# ADuCM410 register map
Vendor: Analog Devices; Series: ADuCM410; File version: 1p0
CPU: CM33 r0p1, little endian, MPU, FPU, 3 interrupt priority bits
Registers are 32-bit, read-write, reset 0x0 unless marked. A register's access mark holds for its fields unless they carry their own. Offsets are from the block's base; [hi:lo] are bit positions; {n}, {i} and the like mark numbered series; 'fields as' and 'values as' point back to an identical list.

## I2C0 — Some Description.
Base 0x40020800
Same registers: I2C1 0x40020C00, I2C2 0x40021000
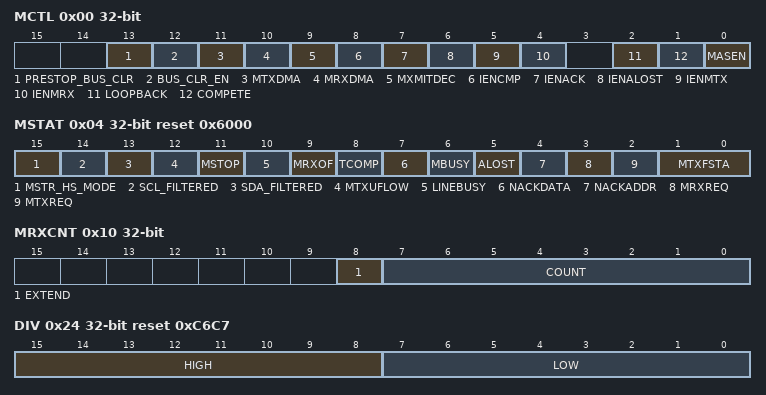
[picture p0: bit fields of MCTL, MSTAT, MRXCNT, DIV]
0x00 MCTL — Master Control
  [13] PRESTOP_BUS_CLR range 0x00000000..0x00000001 — Prestop Bus-Clear
  [12] BUS_CLR_EN range 0x00000000..0x00000001 — Bus-Clear Enable
  [11] MTXDMA wo range 0x00000000..0x00000001 — Enable Master Tx DMA Request
  [10] MRXDMA wo range 0x00000000..0x00000001 — Enable Master Rx DMA Request
  [9] MXMITDEC range 0x00000000..0x00000001 — Decrement Master TX FIFO Status When Transmitted One Byte
  [8] IENCMP range 0x00000000..0x00000001 — Transaction Completed (Or Stop Detected) Interrupt Enable
  [7] IENACK range 0x00000000..0x00000001 — ACK Not Received Interrupt Enable
  [6] IENALOST range 0x00000000..0x00000001 — Arbitration Lost Interrupt Enable
  [5] IENMTX range 0x00000000..0x00000001 — Transmit Request Interrupt Enable.
  [4] IENMRX range 0x00000000..0x00000001 — Receive Request Interrupt Enable
  [2] LOOPBACK range 0x00000000..0x00000001 — Internal Loopback Enable
  [1] COMPETE range 0x00000000..0x00000001 — Start Back-off Disable
  [0] MASEN range 0x00000000..0x00000001 — Master Enable
0x04 MSTAT reset 0x6000 — Master Status
  [15] MSTR_HS_MODE ro — Master High Speed Mode Flag
  [14] SCL_FILTERED ro — State of SCL Line
  [13] SDA_FILTERED ro — State of SDA Line
  [12] MTXUFLOW ro — Master Transmit Underflow
  [11] MSTOP ro — STOP Driven by This I2C Master
  [10] LINEBUSY ro — Line is Busy
  [9] MRXOF ro — Master Receive FIFO Overflow
  [8] TCOMP ro — Transaction Complete or Stop Detected
  [7] NACKDATA ro — ACK Not Received in Response to Data Write
  [6] MBUSY ro — Master Busy
  [5] ALOST ro — Arbitration Lost
  [4] NACKADDR ro — ACK Not Received in Response to an Address
  [3] MRXREQ ro — Master Receive Request
  [2] MTXREQ range 0x00000000..0x00000001 — Master Transmit Interrupt Bit
  [1:0] MTXFSTA ro — Master Transmit FIFO Status
0x08 MRX — Master Receive Data
  [7:0] ICMRX ro — Master Receive Register
0x0C MTX — Master Transmit Data
  [7:0] I2CMRX range 0x00000000..0x000000FF — Master Transmit Register
0x10 MRXCNT — Master Receive Data Count
  [8] EXTEND range 0x00000000..0x00000001 — Extended Read
  [7:0] COUNT range 0x00000000..0x000000FF — Receive Count
0x14 MCRXCNT — Master Current Receive Data Count
  [7:0] COUNT ro — Current Receive Count
0x18 ADDR0 — 1st Master Address Byte
  [7:0] ADR1 range 0x00000000..0x000000FF — Address Byte 1
0x1C ADDR1 — 2nd Master Address Byte
  [7:0] ADR2 range 0x00000000..0x000000FF — Address Byte 2
0x20 BYT — Start Byte
  [7:0] SBYTE range 0x00000000..0x000000FF
0x24 DIV reset 0xC6C7 — Serial Clock Period Divisor
  [15:8] HIGH range 0x00000000..0x000000FF — Serial Clock High Time
  [7:0] LOW range 0x00000000..0x000000FF — Serial Clock Low Time
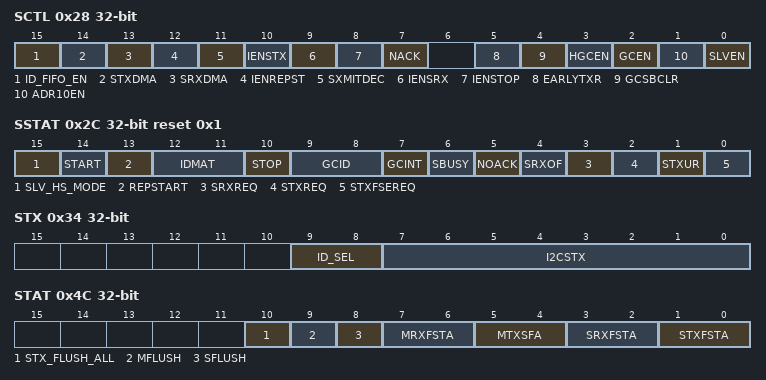
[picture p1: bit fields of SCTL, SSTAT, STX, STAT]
0x28 SCTL — Slave Control
  [15] ID_FIFO_EN range 0x00000000..0x00000001 — ID FIFO Enable
  [14] STXDMA range 0x00000000..0x00000001 — Enable Slave Tx DMA Request
  [13] SRXDMA range 0x00000000..0x00000001 — Enable Slave Rx DMA Request
  [12] IENREPST range 0x00000000..0x00000001 — Repeated Start Interrupt Enable
  [11] SXMITDEC range 0x00000000..0x00000001 — Decrement Slave Tx FIFO Status When Transmitted a Byte
  [10] IENSTX range 0x00000000..0x00000001 — Slave Transmit Request Interrupt Enable
  [9] IENSRX range 0x00000000..0x00000001 — Slave Receive Request Interrupt Enable
  [8] IENSTOP range 0x00000000..0x00000001 — Stop Condition Detected Interrupt Enable
  [7] NACK range 0x00000000..0x00000001 — NACK Next Communication
  [5] EARLYTXR range 0x00000000..0x00000001 — Early Transmit Request Mode
  [4] GCSBCLR wo range 0x00000000..0x00000001 — General Call Status Bit Clear
  [3] HGCEN range 0x00000000..0x00000001 — Hardware General Call Enable
  [2] GCEN range 0x00000000..0x00000001 — General Call Enable
  [1] ADR10EN range 0x00000000..0x00000001 — Enabled 10-bit Addressing
  [0] SLVEN range 0x00000000..0x00000001 — Slave Enable
0x2C SSTAT reset 0x1 — Slave I2C Status/Error/IRQ
  [15] SLV_HS_MODE ro — Slave High Speed Mode Flag
  [14] START ro — Start and Matching Address
  [13] REPSTART ro — Repeated Start and Matching Address
  [12:11] IDMAT ro — Device ID Matched
    {v}=ID{v} (Received Address Matched ID Register {v}) (v=0..3)
  [10] STOP ro — Stop After Start and Matching Address
  [9:8] GCID ro — General ID
    0=NONE (No general call); 1=RESETPROGADDR (General call Reset and Program Address); 2=PROGADDR (General Call Program Address); 3=MATCHID (General Call Matching Alternative ID)
  [7] GCINT ro — General Call Interrupt
  [6] SBUSY ro — Slave Busy
  [5] NOACK ro — Ack Not Generated by the Slave
  [4] SRXOF ro — Slave Receive FIFO Overflow
  [3] SRXREQ ro — Slave Receive Request
  [2] STXREQ ro — Slave Transmit Interrupt Bit
  [1] STXUR ro — Slave Transmit FIFO Underflow
  [0] STXFSEREQ range 0x00000000..0x00000001 — Slave Tx FIFO Status or Early Request
0x30 SRX — Slave Receive
  [7:0] I2CSRX ro — Slave Receive Register
0x34 STX — Slave Transmit
  [9:8] ID_SEL — ID FIFO Selection
    {v}=FIFO{v} (Select Address Matched ID Register {v}) (v=0..3)
  [7:0] I2CSTX range 0x00000000..0x000000FF — Slave Transmit Register
0x38 ALT — Hardware General Call ID
  [7:0] ALT range 0x00000000..0x000000FF — Slave Alt
0x3C ID0 — 1st Slave Address Device ID
  [7:0] ID0 range 0x00000000..0x000000FF — Slave Device ID 0
0x40 ID1 — 2nd Slave Address Device ID
  [7:0] ID1 range 0x00000000..0x000000FF — Slave Device ID 1
0x44 ID2 — 3rd Slave Address Device ID
  [7:0] ID2 range 0x00000000..0x000000FF — Slave Device ID 2
0x48 ID3 — 4th Slave Address Device ID
  [7:0] ID3 range 0x00000000..0x000000FF — Slave Device ID 3
0x4C STAT — Master and Slave FIFO Status
  [10] STX_FLUSH_ALL range 0x00000000..0x00000001 — Flush All the Slave Transmit ID FIFOs.
  [9] MFLUSH wo range 0x00000000..0x00000001 — Flush the Master Transmit FIFO
  [8] SFLUSH wo range 0x00000000..0x00000001 — Flush the Slave Transmit FIFO
  [7:6] MRXFSTA ro — Master Receive FIFO Status
    0=EMPTY (FIFO Empty); 1=ONE (1 Bytes In The FIFO); 2=TWO (2 Bytes in the FIFO)
  [5:4] MTXSFA ro — Master Transmit FIFO Status
    0=EMPTY (FIFO Empty); 1=ONE (1 Bytes in the FIFO); 2=TWO (2 Bytes in the FIFO)
  [3:2] SRXFSTA ro — Slave Receive FIFO Status
    values as MTXSFA
  [1:0] STXFSTA ro — Slave Transmit FIFO Status
    values as MTXSFA
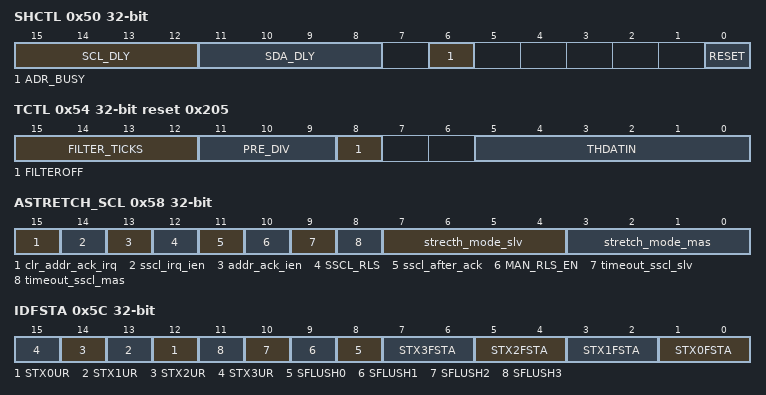
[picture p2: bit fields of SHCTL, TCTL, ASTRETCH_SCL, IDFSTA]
0x50 SHCTL — Shared Control
  [15:12] SCL_DLY range 0x00000000..0x0000000F — Delay Between SCLOUT and SCLOEN
  [11:8] SDA_DLY range 0x00000000..0x0000000F — Delay Between SDAOUT and SDAOEN
  [6] ADR_BUSY ro — ADR Busy Flag
  [0] RESET wo range 0x00000000..0x00000001 — Reset START STOP Detect Circuit
0x54 TCTL reset 0x205 — Timing Control Register
  [15:12] FILTER_TICKS range 0x00000000..0x0000000F — SCK & SDA Gglitch Filter Ticks.
  [11:9] PRE_DIV range 0x00000000..0x00000007 — Presale Divide Counter for SCK DIV
  [8] FILTEROFF range 0x00000000..0x00000001 — Input Filter Control
  [5:0] THDATIN range 0x00000000..0x0000003F — Data in Hold Start
0x58 ASTRETCH_SCL — Automatic Stretch SCL Register
  [15] clr_addr_ack_irq wo range 0x00000000..0x00000001 — Write Clear the Address ACK IRQ.
  [14] sscl_irq_ien range 0x00000000..0x00000001 — Slave Stretch Interruption Enable
  [13] addr_ack_ien range 0x00000000..0x00000001 — Slave ADDRESS ACK Interruption Enable
  [12] SSCL_RLS range 0x00000000..0x00000001 — Slave Manual Clear Stretch
  [11] sscl_after_ack range 0x00000000..0x00000001 — Slave RX Stretch After ACK Mode
  [10] MAN_RLS_EN range 0x00000000..0x00000001 — Manual Release Stretch Enable
  [9] timeout_sscl_slv ro — Slave Automatic Stretch Timeout
  [8] timeout_sscl_mas ro — Master Automatic Stretch Timeout
  [7:4] strecth_mode_slv range 0x00000000..0x0000000F — Slave Automatic Stretch Mode
  [3:0] stretch_mode_mas range 0x00000000..0x0000000F — Master Automatic Stretch Mode
0x5C IDFSTA — ID FIFO Status Register
  [n+12] STX{n}UR ro (n=0..3) — Slave Transmit ID{n} FIFO Underflow
  [n+8] SFLUSH{n} wo range 0x00000000..0x00000001 (n=0..3) — Flush the Slave Transmit ID{n} FIFO
  [2n+1:2n] STX{n}FSTA ro (n=0..3) — Slave Transmit ID{n} FIFO Status
    values as STAT.MTXSFA
0x60 SLV_ADDR1 — Slave 10 Bits Address 1st Byte.
  [7:0] SLV_ADR1 range 0x00000000..0x000000FF — Slave 10 Bits Address 1st Byte
0x64 SLV_ADDR2 — Slave 10 Bits Address 2nd Byte.
  [7:0] SLV_ADR2 range 0x00000000..0x000000FF — Slave 10 Bit Address 2nd Byte
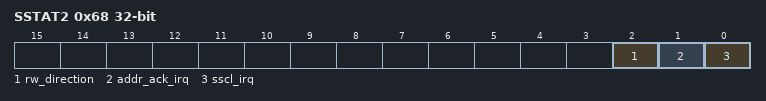
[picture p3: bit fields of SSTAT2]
0x68 SSTAT2 — Slave I2C Status/IRQ 2
  [2] rw_direction ro — Slave I2C RW Direction.
  [1] addr_ack_irq ro — Slave ADDR ACK Interruption State.
  [0] sscl_irq ro — Stretch Interruption State.
